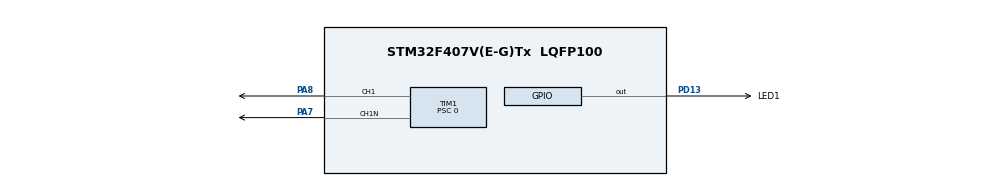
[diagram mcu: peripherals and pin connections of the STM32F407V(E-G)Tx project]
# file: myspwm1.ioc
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Mcu.Family=STM32F4
Mcu.Name=STM32F407V(E-G)Tx
Mcu.Package=LQFP100
NVIC.PriorityGroup=NVIC_PRIORITYGROUP_0
PA13.Mode=Serial_Wire
PA13.Signal=SYS_JTMS-SWDIO
PA14.Mode=Serial_Wire
PA14.Signal=SYS_JTCK-SWCLK
PA7.GPIO_ModeDefaultPP=GPIO_MODE_AF_PP
PA7.GPIO_PuPd=GPIO_PULLDOWN
PA7.GPIO_Speed=GPIO_SPEED_FREQ_LOW
PA7.Mode=PWM Generation1 CH1 CH1N
PA7.Signal=TIM1_CH1N
PA8.GPIO_ModeDefaultPP=GPIO_MODE_AF_PP
PA8.GPIO_PuPd=GPIO_PULLDOWN
PA8.GPIO_Speed=GPIO_SPEED_FREQ_LOW
PA8.Signal=S_TIM1_CH1
PD13.GPIO_Label=LED1
PD13.Signal=GPIO_Output
PH0-OSC_IN.Mode=HSE-External-Oscillator
PH0-OSC_IN.Signal=RCC_OSC_IN
PH1-OSC_OUT.Mode=HSE-External-Oscillator
PH1-OSC_OUT.Signal=RCC_OSC_OUT
ProjectManager.HeapSize=0x200
ProjectManager.StackSize=0x400
ProjectManager.TargetToolchain=TrueSTUDIO
RCC.48MHZClocksFreq_Value=48000000
RCC.AHBFreq_Value=168000000
RCC.APB1CLKDivider=RCC_HCLK_DIV4
RCC.APB1Freq_Value=42000000
RCC.APB1TimFreq_Value=84000000
RCC.APB2CLKDivider=RCC_HCLK_DIV2
RCC.APB2Freq_Value=84000000
RCC.APB2TimFreq_Value=168000000
RCC.CortexFreq_Value=168000000
RCC.HCLKFreq_Value=168000000
RCC.HSE_VALUE=8000000
RCC.HSI_VALUE=16000000
RCC.LSE_VALUE=32768
RCC.PLLM=4
RCC.PLLN=168
RCC.PLLQ=7
RCC.PLLSourceVirtual=RCC_PLLSOURCE_HSE
RCC.SYSCLKFreq_VALUE=168000000
RCC.SYSCLKSource=RCC_SYSCLKSOURCE_PLLCLK
RCC.VCOOutputFreq_Value=336000000
SH.S_TIM1_CH1.0=TIM1_CH1,PWM Generation1 CH1 CH1N
TIM1.Channel-PWM\ Generation1\ CH1\ CH1N=TIM_CHANNEL_1
TIM1.CounterMode=TIM_COUNTERMODE_CENTERALIGNED3
TIM1.DeadTime=10
TIM1.Period=8399
TIM1.Prescaler=0
TIM1.Pulse-PWM\ Generation1\ CH1\ CH1N=300
VP_TIM1_VS_ClockSourceINT.Mode=Internal
board=STM32F4DISCOVERY

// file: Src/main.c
/* USER CODE BEGIN Header */
/**
  ******************************************************************************
  * @file           : main.c
  * @brief          : Main program body
  ******************************************************************************
  ** This notice applies to any and all portions of this file
  * that are not between comment pairs USER CODE BEGIN and
  * USER CODE END. Other portions of this file, whether
  * inserted by the user or by software development tools
  * are owned by their respective copyright owners.
  *
  * COPYRIGHT(c) 2019 STMicroelectronics
  *
  * Redistribution and use in source and binary forms, with or without modification,
  * are permitted provided that the following conditions are met:
  *   1. Redistributions of source code must retain the above copyright notice,
  *      this list of conditions and the following disclaimer.
  *   2. Redistributions in binary form must reproduce the above copyright notice,
  *      this list of conditions and the following disclaimer in the documentation
  *      and/or other materials provided with the distribution.
  *   3. Neither the name of STMicroelectronics nor the names of its contributors
  *      may be used to endorse or promote products derived from this software
  *      without specific prior written permission.
  *
  * THIS SOFTWARE IS PROVIDED BY THE COPYRIGHT HOLDERS AND CONTRIBUTORS "AS IS"
  * AND ANY EXPRESS OR IMPLIED WARRANTIES, INCLUDING, BUT NOT LIMITED TO, THE
  * IMPLIED WARRANTIES OF MERCHANTABILITY AND FITNESS FOR A PARTICULAR PURPOSE ARE
  * DISCLAIMED. IN NO EVENT SHALL THE COPYRIGHT HOLDER OR CONTRIBUTORS BE LIABLE
  * FOR ANY DIRECT, INDIRECT, INCIDENTAL, SPECIAL, EXEMPLARY, OR CONSEQUENTIAL
  * DAMAGES (INCLUDING, BUT NOT LIMITED TO, PROCUREMENT OF SUBSTITUTE GOODS OR
  * SERVICES; LOSS OF USE, DATA, OR PROFITS; OR BUSINESS INTERRUPTION) HOWEVER
  * CAUSED AND ON ANY THEORY OF LIABILITY, WHETHER IN CONTRACT, STRICT LIABILITY,
  * OR TORT (INCLUDING NEGLIGENCE OR OTHERWISE) ARISING IN ANY WAY OUT OF THE USE
  * OF THIS SOFTWARE, EVEN IF ADVISED OF THE POSSIBILITY OF SUCH DAMAGE.
  *
  ******************************************************************************
  */
/* USER CODE END Header */

#include "main.h"
#include "tim.h"
#include "gpio.h"

/* USER CODE BEGIN Includes */
#include "stm32f4xx_it.h"
/* USER CODE END Includes */

/* USER CODE BEGIN PTD */
//extern volatile unsigned int mycntr;
/* USER CODE END PTD */

/* USER CODE BEGIN PV */
unsigned int mypulsewidth=1;
/* USER CODE END PV */

void SystemClock_Config(void);

int main(void)
{

  /* MCU Configuration--------------------------------------------------------*/

  /* Reset of all peripherals, Initializes the Flash interface and the Systick. */

  LL_APB2_GRP1_EnableClock(LL_APB2_GRP1_PERIPH_SYSCFG);
  LL_APB1_GRP1_EnableClock(LL_APB1_GRP1_PERIPH_PWR);

  NVIC_SetPriorityGrouping(NVIC_PRIORITYGROUP_0);

  /* System interrupt init*/

  /* Configure the system clock */
  SystemClock_Config();

  /* Initialize all configured peripherals */
  MX_GPIO_Init();
  MX_TIM1_Init();
  /* USER CODE BEGIN 2 */
  HAL_TIM_PWM_Start_IT(&htim1, TIM_CHANNEL_1);
  HAL_TIMEx_PWMN_Start_IT(&htim1,TIM_CHANNEL_1);
  /* USER CODE END 2 */

  /* Infinite loop */
  while (1)
  {

    /* USER CODE BEGIN 3 */
	  if (mycntr>=10)
	  {
		  mycntr=0;
		  htim1.Instance->CCR1 = mypulsewidth;
		  mypulsewidth++;
		  HAL_GPIO_TogglePin(LED1_GPIO_Port, LED1_Pin);
	  }

  }
  /* USER CODE END 3 */
}

void SystemClock_Config(void)
{
  LL_FLASH_SetLatency(LL_FLASH_LATENCY_5);

  if(LL_FLASH_GetLatency() != LL_FLASH_LATENCY_5)
  {
  Error_Handler();
  }
  LL_PWR_SetRegulVoltageScaling(LL_PWR_REGU_VOLTAGE_SCALE1);
  LL_RCC_HSE_Enable();

   /* Wait till HSE is ready */
  while(LL_RCC_HSE_IsReady() != 1)
  {

  }
  LL_RCC_PLL_ConfigDomain_SYS(LL_RCC_PLLSOURCE_HSE, LL_RCC_PLLM_DIV_4, 168, LL_RCC_PLLP_DIV_2);
  LL_RCC_PLL_Enable();

   /* Wait till PLL is ready */
  while(LL_RCC_PLL_IsReady() != 1)
  {

  }
  LL_RCC_SetAHBPrescaler(LL_RCC_SYSCLK_DIV_1);
  LL_RCC_SetAPB1Prescaler(LL_RCC_APB1_DIV_4);
  LL_RCC_SetAPB2Prescaler(LL_RCC_APB2_DIV_2);
  LL_RCC_SetSysClkSource(LL_RCC_SYS_CLKSOURCE_PLL);

   /* Wait till System clock is ready */
  while(LL_RCC_GetSysClkSource() != LL_RCC_SYS_CLKSOURCE_STATUS_PLL)
  {

  }
  LL_Init1msTick(168000000);
  LL_SYSTICK_SetClkSource(LL_SYSTICK_CLKSOURCE_HCLK);
  LL_SetSystemCoreClock(168000000);
}

void Error_Handler(void)
{
}

/************************ (C) COPYRIGHT STMicroelectronics *****END OF FILE****/
